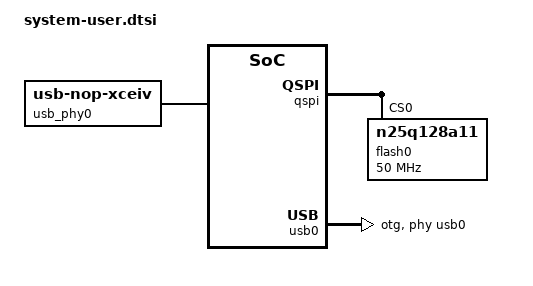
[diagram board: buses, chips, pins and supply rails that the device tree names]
/include/ "system-conf.dtsi"
/include/ "port-config.dtsi"
/ {

   xlnk {
      compatible = "xlnx,xlnk-1.0";
   };

};

/* QSPI partitions are defined with petalinux-config and described in system.conf.dtsi */
&qspi {
   #address-cells = <1>;
   #size-cells = <0>;
   status = "okay";
   is-dual = <0>;
   num-cs = <1>;
   flash0: flash@0 {
      compatible = "n25q128a11";
      reg = <0x0>;
      spi-tx-bus-width = <1>;
      spi-rx-bus-width = <4>;
      spi-max-frequency = <50000000>;      
      #address-cells = <1>;
      #size-cells = <1>;
   };
};

/ {
    usb_phy0:usb_phy@0 {
        compatible="usb-nop-xceiv";
        #phy-cells = <0>;
    };
};


&usb0 {
    dr_mode = "otg";
    usb-phy = <&usb0>;
};


/* Ethernet wiring (FMC ports 0-2 = PL AXI Ethernet, FMC port 3 = PS GEM1,
 * board RJ45 = PS GEM0, their PHYs and MACs) comes from port-config.dtsi
 * (ports-0123-axieth overlay, included above); GEM0 and GEM1 must stay
 * enabled. The overlay gives gem0 a phy-handle and an MDIO child, so 2025.01
 * u-boot no longer data-aborts probing it (that crash needs a gem0 without a
 * PHY description). This dtb is also u-boot's control DT (BOOT.BIN loads it
 * at 0x100000).
 * board RJ45 = PS GEM0 on MIO16-27, Marvell 88E151x on the PicoZed SOM at
 * MDIO address 0, rgmii-id, as the overlay describes it. */
